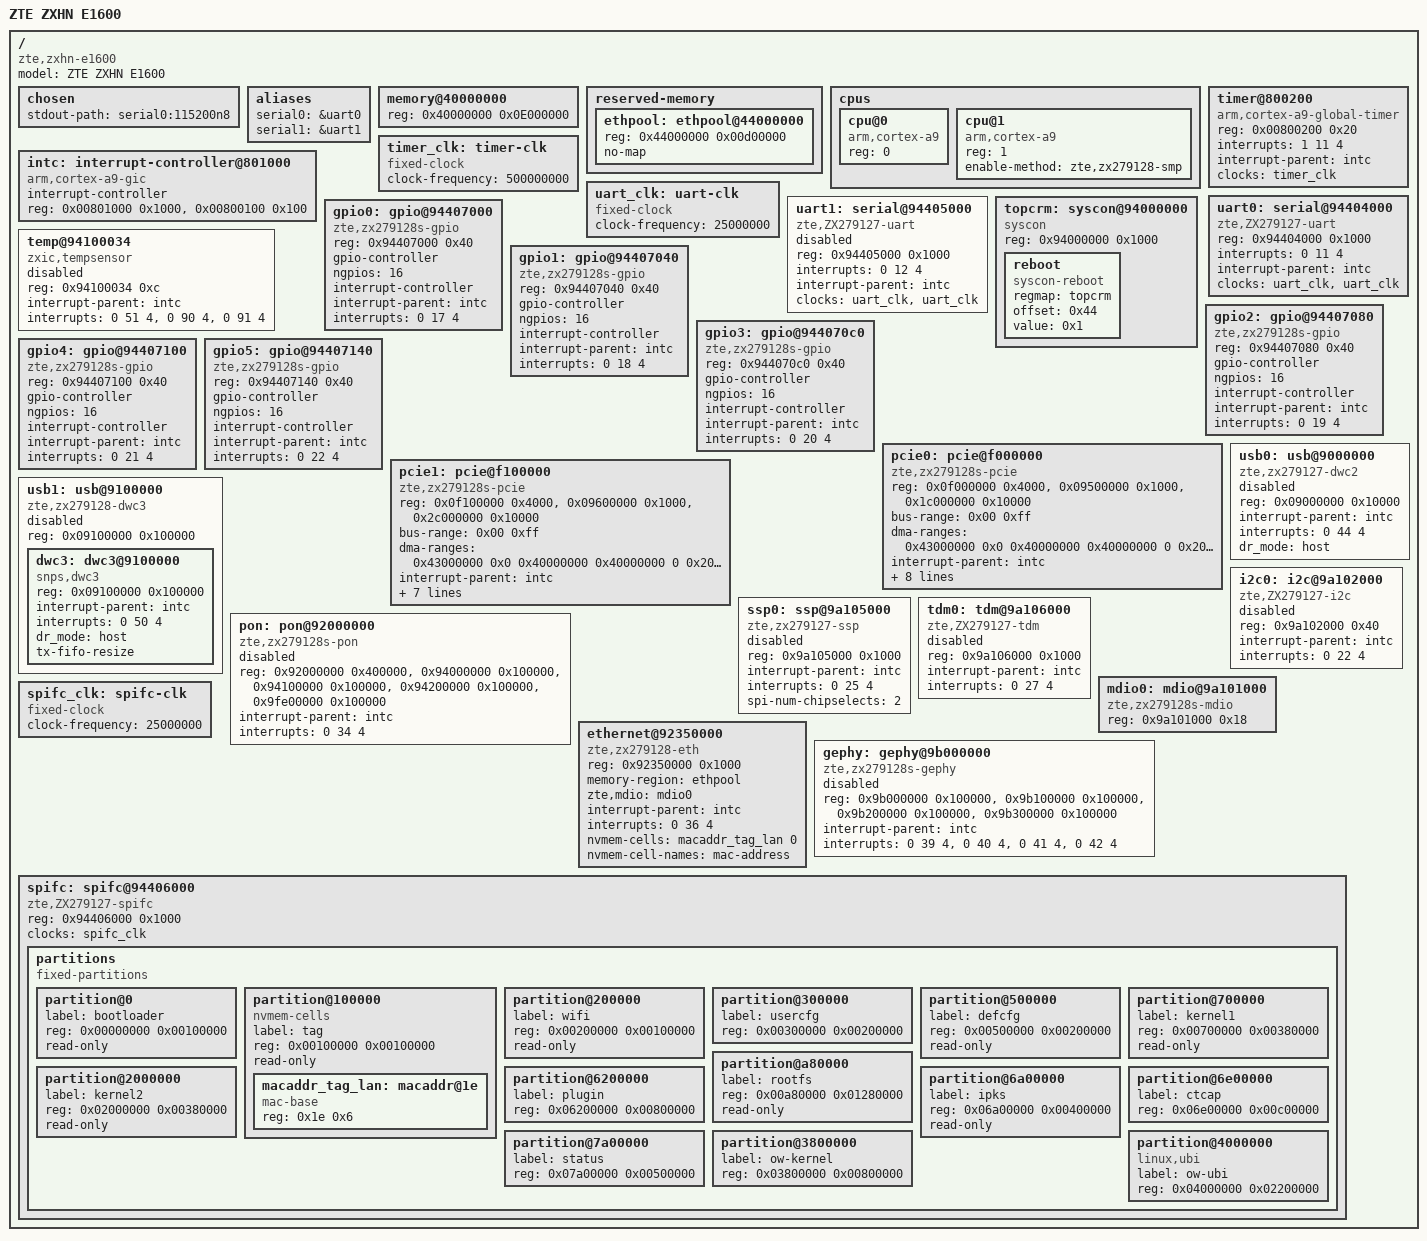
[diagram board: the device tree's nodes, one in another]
/dts-v1/;

#include <dt-bindings/gpio/gpio.h>

/ {
    #address-cells = <1>;
    #size-cells = <1>;

    model = "ZTE ZXHN E1600";
    compatible = "zte,zxhn-e1600", "zte,zx279128s";

    chosen {
        stdout-path = "serial0:115200n8";
    };

    aliases {
        serial0 = &uart0;
        serial1 = &uart1;
    };

    /* 224 MiB of the 256 MiB board RAM: the stock firmware keeps a
     * reservation around 0x4e700000 that must stay untouched, so Linux
     * allocations stop at 0x4e000000 (see extraction plan mem=224M note).
     * The top 13 MiB below that limit is carved out below as the
     * Ethernet buffer pool. */
    memory@40000000 {
        device_type = "memory";
        reg = <0x40000000 0x0E000000>;
    };

    reserved-memory {
        #address-cells = <1>;
        #size-cells = <1>;
        ranges;

        /* Ethernet buffer pool: 2048x2 KiB buffer descriptors +
         * BE16 lookup tables + 8 RX rings + DMA status ring + TX
         * ring (layout in zx279128-mac.c). no-map + driver ioremap
         * keeps it uncached, matching how U-Boot drives the same
         * hardware; the DMA engines are cache-unaware.
         * Address choice: must stay clear of the kernel Image
         * (ends ~0x40fc0000) AND of the appended DTB, which U-Boot
         * leaves in place right after the decompressed kernel
         * (~0x413eb000) and which the kernel reserves early — a
         * pool at 0x41000000 collided with that DTB reservation
         * and failed with -EBUSY (Gate G4 attempt 1, 2026-10-01).
         * 0x44000000 was the uImage load address, dead after bootm;
         * pool end 0x44d00000 is still below the stock reservation
         * at ~0x4e700000. */
        ethpool: ethpool@44000000 {
            reg = <0x44000000 0x00d00000>;
            no-map;
        };
    };

    cpus {
        #address-cells = <1>;
        #size-cells = <0>;

        cpu@0 {
            device_type = "cpu";
            compatible = "arm,cortex-a9";
            reg = <0>;
        };

        cpu@1 {
            device_type = "cpu";
            compatible = "arm,cortex-a9";
            reg = <1>;
            enable-method = "zte,zx279128-smp";
        };
    };

    intc: interrupt-controller@801000 {
        compatible = "arm,cortex-a9-gic";
        /*
         * A GIC is a leaf interrupt controller: it must NOT carry
         * #address-cells/#size-cells. When present they leak into
         * of_irq_parse_imap_parent() while resolving the PCIe
         * interrupt-map: addrsize becomes 1, so the parent specifier
         * "<&intc 0 63 4>" is read shifted by one cell (type=63
         * instead of SPI 0) and gic_irq_domain_translate() rejects it
         * (-EINVAL). The endpoint then gets dev->irq == 0, the INTx
         * fallback in pci_alloc_irq_vectors_affinity() is skipped, and
         * mt7915e probe fails with -ENOTSUPP (-524). The H3600
         * reference GIC node has no #address-cells for exactly this
         * reason.
         */
        #interrupt-cells = <3>;
        interrupt-controller;
        reg = <0x00801000 0x1000>, <0x00800100 0x100>;
    };

    timer@800200 {
        compatible = "arm,cortex-a9-global-timer";
        reg = <0x00800200 0x20>;
        interrupts = <1 11 4>;
        interrupt-parent = <&intc>;
        clocks = <&timer_clk>;
    };

    timer_clk: timer-clk {
        compatible = "fixed-clock";
        #clock-cells = <0>;
        clock-frequency = <500000000>;
    };

    /* SoC oscillator: exactly 25.000 MHz. The live IBRD=13/FBRD=36
     * divider readback at 115200n8 implies 115200*16*(13+36/64) =
     * 24998400 Hz — that is the divider's approximation of 115200
     * from a true 25 MHz clock, not the clock rate itself. */
    uart_clk: uart-clk {
        compatible = "fixed-clock";
        #clock-cells = <0>;
        clock-frequency = <25000000>;
    };

    uart0: serial@94404000 {
        compatible = "zte,ZX279127-uart";
        reg = <0x94404000 0x1000>;
        interrupts = <0 11 4>;
        interrupt-parent = <&intc>;
        clocks = <&uart_clk>, <&uart_clk>;
        clock-names = "uartclk", "apb_pclk";
        status = "okay";
    };

    /* Second UART (stock serial@0x94405000, SPI 12, enabled in stock
     * DT — stock boot log shows it as ttyAMA1). Disabled here:
     * zx279128-uart.c hardcodes port->line = 0 so a second instance
     * cannot register until line comes from of_alias_get_id, and the
     * UART1 pad routing on E1600 is unconfirmed (Phase 5 pin hunt). */
    uart1: serial@94405000 {
        compatible = "zte,ZX279127-uart";
        reg = <0x94405000 0x1000>;
        interrupts = <0 12 4>;
        interrupt-parent = <&intc>;
        clocks = <&uart_clk>, <&uart_clk>;
        clock-names = "uartclk", "apb_pclk";
        status = "disabled";
    };

    /* Warm-reset path recovered from U-Boot's `reset` command (do_reset ->
     * routine at file 0x21040): it writes 1 to topcrm+0x44.
     *   mov r3,#0x94000000 ; mov r2,#1 ; str r2,[r3,#0x44] ; bx lr
     * topcrm@94000000 is the vendor "zte,ZX279127-topcrm","syscon" block.
     * Exposing it as a syscon + syscon-reboot child gives machine_restart()
     * a real register-write reset so `reboot`/`echo b > /proc/sysrq-trigger`
     * work instead of falling back to soft_restart(0) (which halts here). */
    topcrm: syscon@94000000 {
        compatible = "syscon", "simple-mfd";
        reg = <0x94000000 0x1000>;

        reboot: reboot {
            compatible = "syscon-reboot";
            regmap = <&topcrm>;
            offset = <0x44>;
            value = <0x1>;
        };
    };

    /* SoC thermal sensor (stock temp@94100034, enabled, three IRQs
     * SPI 51/90/91). No upstream driver exists; node documents the
     * block for a future vendor-driver port. */
    temp@94100034 {
        compatible = "zxic,tempsensor";
        reg = <0x94100034 0xc>;
        interrupt-parent = <&intc>;
        interrupts = <0 51 4>, <0 90 4>, <0 91 4>;
        status = "disabled";
    };

    /* GPIO controller: 6 banks x 16 lines at 0x94407000 + n*0x40
     * (driver gpio-zx279133, patch 1002). Flat numbering GPIO_00..63
     * matches datasheet Table 7 pad numbers exactly (bank n line m =
     * GPIO 16n+m), so &gpio3 5 == pad 53 == PCIE0_nCLKREQ etc.
     * IRQs: GIC SPI 17..22, level-high, one per bank. status okay so
     * gpioinfo works for the Phase 5 pin hunt. */
    gpio0: gpio@94407000 {
        compatible = "zte,zx279128s-gpio";
        reg = <0x94407000 0x40>;
        gpio-controller;
        #gpio-cells = <2>;
        ngpios = <16>;
        interrupt-controller;
        #interrupt-cells = <2>;
        interrupt-parent = <&intc>;
        interrupts = <0 17 4>;
        status = "okay";
    };

    gpio1: gpio@94407040 {
        compatible = "zte,zx279128s-gpio";
        reg = <0x94407040 0x40>;
        gpio-controller;
        #gpio-cells = <2>;
        ngpios = <16>;
        interrupt-controller;
        #interrupt-cells = <2>;
        interrupt-parent = <&intc>;
        interrupts = <0 18 4>;
        status = "okay";
    };

    gpio2: gpio@94407080 {
        compatible = "zte,zx279128s-gpio";
        reg = <0x94407080 0x40>;
        gpio-controller;
        #gpio-cells = <2>;
        ngpios = <16>;
        interrupt-controller;
        #interrupt-cells = <2>;
        interrupt-parent = <&intc>;
        interrupts = <0 19 4>;
        status = "okay";
    };

    gpio3: gpio@944070c0 {
        compatible = "zte,zx279128s-gpio";
        reg = <0x944070c0 0x40>;
        gpio-controller;
        #gpio-cells = <2>;
        ngpios = <16>;
        interrupt-controller;
        #interrupt-cells = <2>;
        interrupt-parent = <&intc>;
        interrupts = <0 20 4>;
        status = "okay";
    };

    gpio4: gpio@94407100 {
        compatible = "zte,zx279128s-gpio";
        reg = <0x94407100 0x40>;
        gpio-controller;
        #gpio-cells = <2>;
        ngpios = <16>;
        interrupt-controller;
        #interrupt-cells = <2>;
        interrupt-parent = <&intc>;
        interrupts = <0 21 4>;
        status = "okay";
    };

    gpio5: gpio@94407140 {
        compatible = "zte,zx279128s-gpio";
        reg = <0x94407140 0x40>;
        gpio-controller;
        #gpio-cells = <2>;
        ngpios = <16>;
        interrupt-controller;
        #interrupt-cells = <2>;
        interrupt-parent = <&intc>;
        interrupts = <0 22 4>;
        status = "okay";
    };

    /* PCIe root ports (driver pcie-zx279128, patch 1001). Same SoC as
     * H3600: DBI/ctrl/config bases and outbound windows identical (F3),
     * IRQs match stock E1600 DT (F2: SPI 63 / 78). The MT7915 is a single
     * dual-HIF chip shared by both ports, so its reset/enable pad is pulsed
     * exactly once, from the FIRST probe (pcie0), before either port trains
     * its link - see zx_board_reset_done in the driver. Pad 55
     * (PCIE1_nCLKREQ) is the one stock Linux itself drives as output-HIGH
     * (bank3 DIR=0x84/DATA=0xA0A0 live snapshot) and pulsing it is what
     * brought port 1's link up; pad 53 stays untouched because stock leaves
     * it an input (driving it risks contention with the chip's own
     * CLKREQ# driver). L2C node deliberately absent (F8, Phase 5). */
    pcie0: pcie@f000000 {
        compatible = "zte,zx279128s-pcie";
        /* The "config" window size is deliberately 64 KiB (0x10000),
         * matching the CFG0 iATU window stock programs (base
         * 0x1c000000, limit 0x1c00ffff - see tmp/stock_re2.log OB1),
         * NOT the 2 MiB the aperture reserves. A 2 MiB-aligned base AND
         * 2 MiB size makes ARM __arm_ioremap_pfn_caller take the
         * !SMP/!LPAE remap_area_sections() path, which writes the
         * MT_UNCACHED section descriptor verbatim (PMD_TYPE_SECT|XN,
         * AP=00 = no-access under v7 TEX-remap) and never ORs in the
         * kernel AP bits -> first config read faults (FSR 0x2d,
         * *pgd=1c000052). A non-2 MiB size forces the page-table path
         * (ioremap_page_range) which applies kern_pgprot correctly.
         * Stock never hits this because it is an SMP kernel (page path
         * always). */
        reg = <0x0f000000 0x4000>,   /* DBI registers */
              <0x09500000 0x1000>,   /* ctrl registers */
              <0x1c000000 0x10000>;  /* config window (CFG0 iATU) */
        reg-names = "dbi", "ctrl", "config";
        #address-cells = <3>;
        #size-cells = <2>;
        device_type = "pci";
        bus-range = <0x00 0xff>;
        ranges = <0x82000000 0 0x10000000  0x10000000  0 0x08000000>;
        dma-ranges = <0x43000000 0x0 0x40000000  0x40000000  0 0x20000000>;
        interrupt-parent = <&intc>;
        interrupts = <0 63 4>;
        #interrupt-cells = <1>;
        interrupt-map-mask = <0 0 0 7>;
        interrupt-map = <0 0 0 1 &intc 0 63 4>,
                        <0 0 0 2 &intc 0 63 4>,
                        <0 0 0 3 &intc 0 63 4>,
                        <0 0 0 4 &intc 0 63 4>;
        linux,pci-domain = <0>;
        port-id = <0>;
        enable-gpios = <&gpio3 7 GPIO_ACTIVE_HIGH>;
        status = "okay";
    };

    pcie1: pcie@f100000 {
        compatible = "zte,zx279128s-pcie";
        /* Config window 64 KiB for the same reason as pcie0: avoid the
         * !SMP 2 MiB section-mapping ioremap path (AP=00 fault). */
        reg = <0x0f100000 0x4000>,   /* DBI registers */
              <0x09600000 0x1000>,   /* ctrl registers */
              <0x2c000000 0x10000>;  /* config window (CFG0 iATU) */
        reg-names = "dbi", "ctrl", "config";
        #address-cells = <3>;
        #size-cells = <2>;
        device_type = "pci";
        bus-range = <0x00 0xff>;
        ranges = <0x82000000 0 0x20000000  0x20000000  0 0x08000000>;
        dma-ranges = <0x43000000 0x0 0x40000000  0x40000000  0 0x20000000>;
        interrupt-parent = <&intc>;
        interrupts = <0 78 4>;
        #interrupt-cells = <1>;
        interrupt-map-mask = <0 0 0 7>;
        interrupt-map = <0 0 0 1 &intc 0 78 4>,
                        <0 0 0 2 &intc 0 78 4>,
                        <0 0 0 3 &intc 0 78 4>,
                        <0 0 0 4 &intc 0 78 4>;
        linux,pci-domain = <1>;
        port-id = <1>;
        status = "okay";
    };

    /* USB 2.0 host (stock usb@09000000, dwc2, SPI 44, enabled —
     * stock boot log registers it as USB bus 1). Disabled: needs the
     * vendor lsp0crpm clock provider which our tree does not model;
     * revisit when USB support is scheduled. */
    usb0: usb@9000000 {
        compatible = "zte,zx279127-dwc2";
        reg = <0x09000000 0x10000>;
        interrupt-parent = <&intc>;
        interrupts = <0 44 4>;
        dr_mode = "host";
        status = "disabled";
    };

    /* USB 3.0 host (stock usb@09100000, dwc3 → xhci, SPI 50, enabled
     * — stock boot log registers it as USB bus 2; stock log also shows
     * a benign "mapping for 0x09100000 out of vmalloc space" BUG from
     * the vendor DT memory reservation quirk). Disabled: same clock
     * dependency as usb0. */
    usb1: usb@9100000 {
        compatible = "zte,zx279128-dwc3";
        reg = <0x09100000 0x100000>;
        #address-cells = <1>;
        #size-cells = <1>;
        ranges;
        status = "disabled";

        dwc3: dwc3@9100000 {
            compatible = "snps,dwc3";
            reg = <0x09100000 0x100000>;
            interrupt-parent = <&intc>;
            interrupts = <0 50 4>;
            dr_mode = "host";
            tx-fifo-resize;
        };
    };

    /* I2C0 (stock i2c@9a102000, enabled, SPI 22). NOTE: SPI 22 is
     * also our gpio5 bank IRQ — verify whether they truly share the
     * line (would need IRQF_SHARED) before enabling both. Likely the
     * SFP/PON module management bus. Disabled: no clock driver
     * (lsp1crpm) and no confirmed attached device yet. */
    i2c0: i2c@9a102000 {
        compatible = "zte,ZX279127-i2c";
        reg = <0x9a102000 0x40>;
        interrupt-parent = <&intc>;
        interrupts = <0 22 4>;
        status = "disabled";
    };

    /* SSP SPI controller (stock ssp@9a105000, enabled, SPI 25; stock
     * DT models a rohm,dh2228fv fTPM on CS0 — population on E1600
     * unconfirmed). Disabled: no clock driver, TPM presence
     * unverified. */
    ssp0: ssp@9a105000 {
        compatible = "zte,zx279127-ssp";
        reg = <0x9a105000 0x1000>;
        interrupt-parent = <&intc>;
        interrupts = <0 25 4>;
        spi-num-chipselects = <2>;
        #address-cells = <1>;
        #size-cells = <0>;
        status = "disabled";
    };

    /* Voice/audio TDM (stock tdm@9a106000, enabled, SPI 27).
     * Disabled: no driver, no planned use on this port. */
    tdm0: tdm@9a106000 {
        compatible = "zte,ZX279127-tdm";
        reg = <0x9a106000 0x1000>;
        interrupt-parent = <&intc>;
        interrupts = <0 27 4>;
        status = "disabled";
    };

    /* GPON PON block (stock pon@92000000, enabled, SPI 34). The GPON
     * uplink is a future phase — vendor driver stack only; this node
     * documents the five register windows from the stock DT. */
    pon: pon@92000000 {
        compatible = "zte,zx279128s-pon";
        reg = <0x92000000 0x400000>, <0x94000000 0x100000>,
              <0x94100000 0x100000>, <0x94200000 0x100000>,
              <0x9fe00000 0x100000>;
        interrupt-parent = <&intc>;
        interrupts = <0 34 4>;
        status = "disabled";
    };

    /* MDIO controller from the stock DT (mdio@9a101000,
     * clocks = <&lsp1crpm 1>). The block clock is left in the
     * bootloader-configured state (vendor driver never touches clocks;
     * same convention as uart0/spifc here), so no clocks property.
     * No child PHY nodes yet: of_mdiobus_register() scans all 32
     * addresses; the four integrated GEPHYs should appear as C22
     * devices once Stage B confirms their addresses. */
    mdio0: mdio@9a101000 {
        compatible = "zte,zx279128s-mdio";
        reg = <0x9a101000 0x18>;
        #address-cells = <1>;
        #size-cells = <0>;
        status = "okay";
    };

    /* Integrated 4-port Ethernet (MAC + packet processor + BMU/TM/RED
     * + DMA). All register block bases are fixed SoC addresses known
     * to the driver (decompiler-verified from U-Boot's drivers);
     * reg names the node only. The driver attaches the four GEPHYs
     * at mdio0 addresses 10..13 and exposes eth0..eth3 = LAN3, LAN2,
     * LAN1, WAN (verified by moving a cable between the jacks). */
    ethernet@92350000 {
        compatible = "zte,zx279128-eth";
        reg = <0x92350000 0x1000>;
        memory-region = <&ethpool>;
        zte,mdio = <&mdio0>;
        /* TM interrupt (stock tm@92340000, SPI 36), used when use_irq=1 */
        interrupt-parent = <&intc>;
        interrupts = <0 36 4>;
        nvmem-cells = <&macaddr_tag_lan 0>;
        nvmem-cell-names = "mac-address";
        status = "okay";
    };

    /* Integrated 4-port GbE PHY block (stock DT gephy@9b000000:
     * four 1 MiB register windows + per-port IRQs 39-42, level-high).
     * Inert for now — the vendor driver drives it through a vendor
     * "common switch" stack, not phylib; Stage D/E will decide how to
     * expose it. Kept documented and disabled. */
    gephy: gephy@9b000000 {
        compatible = "zte,zx279128s-gephy";
        reg = <0x9b000000 0x100000>,
              <0x9b100000 0x100000>,
              <0x9b200000 0x100000>,
              <0x9b300000 0x100000>;
        interrupt-parent = <&intc>;
        interrupts = <0 39 4>, <0 40 4>, <0 41 4>, <0 42 4>;
        status = "disabled";
    };

    /* SPIFC runs from the 25 MHz nandflash clock family (stock debug tree
     * reports lb_nandflash_100m_wclk = 25 MHz with nand_wclk_sel = 25 MHz).
     * This is deliberately a separate fixed clock: uart_clk is the same
     * nominal rate but must not be shared with the flash controller. */
    spifc_clk: spifc-clk {
        compatible = "fixed-clock";
        #clock-cells = <0>;
        clock-frequency = <25000000>;
    };

    spifc: spifc@94406000 {
        compatible = "zte,ZX279127-spifc";
        reg = <0x94406000 0x1000>;
        clocks = <&spifc_clk>;

        partitions {
            compatible = "fixed-partitions";
            #address-cells = <1>;
            #size-cells = <1>;

            partition@0 {
                label = "bootloader";
                reg = <0x00000000 0x00100000>;
                read-only;
            };

            partition@100000 {
                compatible = "nvmem-cells";
                #address-cells = <1>;
                #size-cells = <1>;
                label = "tag";
                reg = <0x00100000 0x00100000>;
                read-only;

                /* factory TLV record (18 byte header), 6 byte MAC at 0x1e.
                 * mac-base so consumers can derive indexed MACs: index 0 =
                 * LAN base, index 1 = base+1 (WAN / 5 GHz Wi-Fi, stock
                 * convention per plan 7.3 F6). */
                macaddr_tag_lan: macaddr@1e {
                    compatible = "mac-base";
                    reg = <0x1e 0x6>;
                    #nvmem-cell-cells = <1>;
                };
            };

            partition@200000 {
                label = "wifi";
                reg = <0x00200000 0x00100000>;
                read-only;
            };

            partition@300000 {
                label = "usercfg";
                reg = <0x00300000 0x00200000>;
            };

            partition@500000 {
                label = "defcfg";
                reg = <0x00500000 0x00200000>;
                read-only;
            };

            partition@700000 {
                label = "kernel1";
                reg = <0x00700000 0x00380000>;
                read-only;
            };

            partition@a80000 {
                label = "rootfs";
                reg = <0x00a80000 0x01280000>;
                read-only;
            };

            partition@2000000 {
                label = "kernel2";
                reg = <0x02000000 0x00380000>;
                read-only;
            };

            partition@6200000 {
                label = "plugin";
                reg = <0x06200000 0x00800000>;
            };

            partition@6a00000 {
                label = "ipks";
                reg = <0x06a00000 0x00400000>;
                read-only;
            };

            partition@6e00000 {
                label = "ctcap";
                reg = <0x06e00000 0x00c00000>;
            };

            partition@7a00000 {
                label = "status";
                reg = <0x07a00000 0x00500000>;
            };

            /* OpenWrt: raw kernel uImage, then the UBI volume group
             * (squashfs rootfs + overlay). Both sit in flash that stock
             * never uses. */
            partition@3800000 {
                label = "ow-kernel";
                reg = <0x03800000 0x00800000>;
            };

            partition@4000000 {
                compatible = "linux,ubi";
                label = "ow-ubi";
                reg = <0x04000000 0x02200000>;
            };
        };
    };
};
